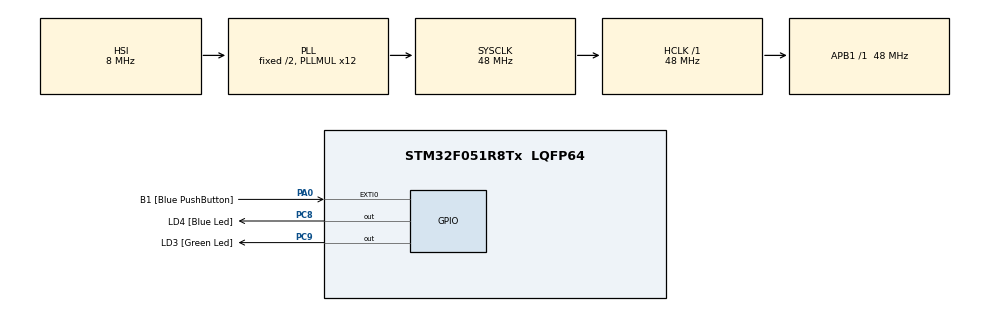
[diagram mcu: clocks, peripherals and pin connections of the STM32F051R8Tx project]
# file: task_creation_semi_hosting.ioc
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FREERTOS.Tasks01=task1,0,128,task1_ef,Default,NULL,Dynamic,NULL,NULL;task2,-2,128,task2_ef,Default,NULL,Dynamic,NULL,NULL
FREERTOS.configUSE_NEWLIB_REENTRANT=1
Mcu.Family=STM32F0
Mcu.Name=STM32F051R8Tx
Mcu.Package=LQFP64
NVIC.TIM6_DAC_IRQn=true\:3\:0\:false\:false\:true\:false\:false\:true\:true
NVIC.TimeBase=TIM6_DAC_IRQn
NVIC.TimeBaseIP=TIM6
PA0.GPIO_Label=B1 [Blue PushButton]
PA0.GPIO_ModeDefaultEXTI=GPIO_MODE_EVT_RISING
PA0.Signal=GPXTI0
PA13.GPIO_Label=SWDIO
PA13.Mode=Serial_Wire
PA13.Signal=SYS_SWDIO
PA14.GPIO_Label=SWCLK
PA14.Mode=Serial_Wire
PA14.Signal=SYS_SWCLK
PC8.GPIO_Label=LD4 [Blue Led]
PC8.Signal=GPIO_Output
PC9.GPIO_Label=LD3 [Green Led]
PC9.Signal=GPIO_Output
ProjectManager.HeapSize=0x200
ProjectManager.StackSize=0x400
ProjectManager.TargetToolchain=STM32CubeIDE
RCC.AHBFreq_Value=48000000
RCC.APB1Freq_Value=48000000
RCC.APB1TimFreq_Value=48000000
RCC.HCLKFreq_Value=48000000
RCC.PLLMUL=RCC_PLL_MUL12
RCC.SYSCLKFreq_VALUE=48000000
RCC.SYSCLKSource=RCC_SYSCLKSOURCE_PLLCLK
VP_FREERTOS_VS_CMSIS_V1.Mode=CMSIS_V1
VP_SYS_VS_tim6.Mode=TIM6
board=STM32F0DISCOVERY

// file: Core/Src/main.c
/* USER CODE BEGIN Header */
/**
  ******************************************************************************
  * @file           : main.c
  * @brief          : Main program body
  ******************************************************************************
  * @attention
  *
  * Copyright (c) 2023 STMicroelectronics.
  * All rights reserved.
  *
  * This software is licensed under terms that can be found in the LICENSE file
  * in the root directory of this software component.
  * If no LICENSE file comes with this software, it is provided AS-IS.
  *
  ******************************************************************************
  */
/* USER CODE END Header */
#include "main.h"
#include "cmsis_os.h"

/* USER CODE BEGIN Includes */
#include <stdio.h>
#include <stdint.h>

/* USER CODE END Includes */

osThreadId task1Handle;
osThreadId task2Handle;

void SystemClock_Config(void);
static void MX_GPIO_Init(void);
void task1_ef(void const * argument);
void task2_ef(void const * argument);

/* USER CODE BEGIN PFP */

#ifdef USE_SEMI_HOSTING
extern void initialise_monitor_handles();
#endif
/* USER CODE END PFP */

int main(void)
{
  /* USER CODE BEGIN 1 */
  #ifdef USE_SEMI_HOSTING
	initialise_monitor_handles();
  #endif

  /* USER CODE END 1 */

  /* MCU Configuration--------------------------------------------------------*/

  /* Reset of all peripherals, Initializes the Flash interface and the Systick. */
  HAL_Init();

  /* Configure the system clock */
  SystemClock_Config();

  /* Initialize all configured peripherals */
  MX_GPIO_Init();

  /* Create the thread(s) */
  /* definition and creation of task1 */
  osThreadDef(task1, task1_ef, osPriorityNormal, 0, 128);
  task1Handle = osThreadCreate(osThread(task1), NULL);

  /* definition and creation of task2 */
  osThreadDef(task2, task2_ef, osPriorityLow, 0, 128);
  task2Handle = osThreadCreate(osThread(task2), NULL);

  /* Start scheduler */
  osKernelStart();
  /* We should never get here as control is now taken by the scheduler */
  /* Infinite loop */
  while (1)
  {

  }
}

void SystemClock_Config(void)
{
  RCC_OscInitTypeDef RCC_OscInitStruct = {0};
  RCC_ClkInitTypeDef RCC_ClkInitStruct = {0};

  /** Initializes the RCC Oscillators according to the specified parameters
  * in the RCC_OscInitTypeDef structure.
  */
  RCC_OscInitStruct.OscillatorType = RCC_OSCILLATORTYPE_HSI;
  RCC_OscInitStruct.HSIState = RCC_HSI_ON;
  RCC_OscInitStruct.HSICalibrationValue = RCC_HSICALIBRATION_DEFAULT;
  RCC_OscInitStruct.PLL.PLLState = RCC_PLL_ON;
  RCC_OscInitStruct.PLL.PLLSource = RCC_PLLSOURCE_HSI;
  RCC_OscInitStruct.PLL.PLLMUL = RCC_PLL_MUL12;
  RCC_OscInitStruct.PLL.PREDIV = RCC_PREDIV_DIV1;
  if (HAL_RCC_OscConfig(&RCC_OscInitStruct) != HAL_OK)
  {
    Error_Handler();
  }

  /** Initializes the CPU, AHB and APB buses clocks
  */
  RCC_ClkInitStruct.ClockType = RCC_CLOCKTYPE_HCLK|RCC_CLOCKTYPE_SYSCLK
                              |RCC_CLOCKTYPE_PCLK1;
  RCC_ClkInitStruct.SYSCLKSource = RCC_SYSCLKSOURCE_PLLCLK;
  RCC_ClkInitStruct.AHBCLKDivider = RCC_SYSCLK_DIV1;
  RCC_ClkInitStruct.APB1CLKDivider = RCC_HCLK_DIV1;

  if (HAL_RCC_ClockConfig(&RCC_ClkInitStruct, FLASH_LATENCY_1) != HAL_OK)
  {
    Error_Handler();
  }
}

static void MX_GPIO_Init(void)
{
  GPIO_InitTypeDef GPIO_InitStruct = {0};

  /* GPIO Ports Clock Enable */
  __HAL_RCC_GPIOA_CLK_ENABLE();
  __HAL_RCC_GPIOC_CLK_ENABLE();

  /*Configure GPIO pin Output Level */
  HAL_GPIO_WritePin(GPIOC, LD4_Pin|LD3_Pin, GPIO_PIN_RESET);

  /*Configure GPIO pin : B1_Pin */
  GPIO_InitStruct.Pin = B1_Pin;
  GPIO_InitStruct.Mode = GPIO_MODE_EVT_RISING;
  GPIO_InitStruct.Pull = GPIO_NOPULL;
  HAL_GPIO_Init(B1_GPIO_Port, &GPIO_InitStruct);

  /*Configure GPIO pins : LD4_Pin LD3_Pin */
  GPIO_InitStruct.Pin = LD4_Pin|LD3_Pin;
  GPIO_InitStruct.Mode = GPIO_MODE_OUTPUT_PP;
  GPIO_InitStruct.Pull = GPIO_NOPULL;
  GPIO_InitStruct.Speed = GPIO_SPEED_FREQ_LOW;
  HAL_GPIO_Init(GPIOC, &GPIO_InitStruct);

}

/* USER CODE BEGIN 4 */

static void prvSetupHardware(void)
{

}

/* USER CODE END 4 */

void task1_ef(void const * argument)
{
  for(;;)
  {
    osDelay(1);
  }
}

void task2_ef(void const * argument)
{
  for(;;)
  {
    osDelay(1);
  }
}

void HAL_TIM_PeriodElapsedCallback(TIM_HandleTypeDef *htim)
{
  if (htim->Instance == TIM6) {
    HAL_IncTick();
  }
}

void Error_Handler(void)
{
  __disable_irq();
  while (1)
  {
  }
}
